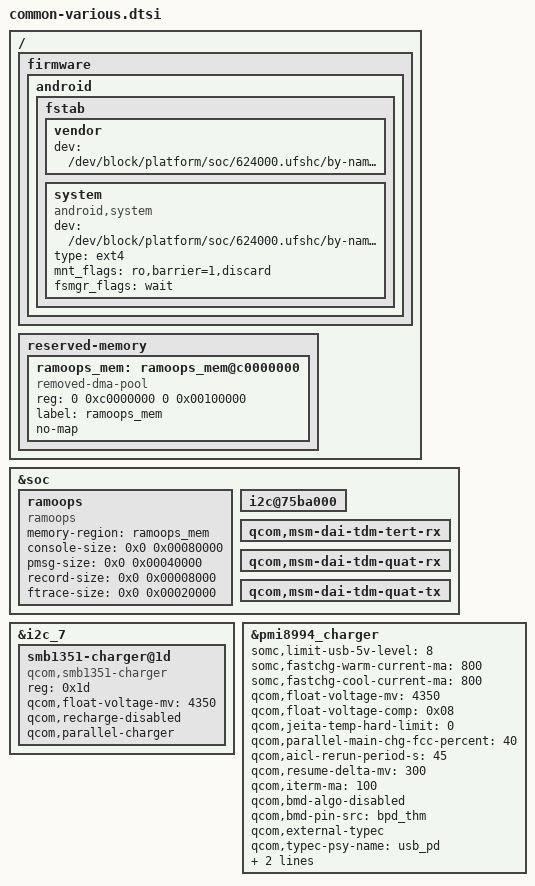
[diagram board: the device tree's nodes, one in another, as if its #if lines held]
/* Copyright (c) 2018 The LineageOS Project. All rights reserved.
 *
 * This program is free software; you can redistribute it and/or modify
 * it under the terms of the GNU General Public License version 2 and
 * only version 2 as published by the Free Software Foundation.
 *
 * This program is distributed in the hope that it will be useful,
 * but WITHOUT ANY WARRANTY; without even the implied warranty of
 * MERCHANTABILITY or FITNESS FOR A PARTICULAR PURPOSE.  See the
 * GNU General Public License for more details.
 */

/ {
	firmware: firmware {
		android {
			/delete-node/ vbmeta;
			fstab {
#ifdef CONFIG_LGE_MSM8996_ENABLE_VENDOR
				vendor {
					dev = "/dev/block/platform/soc/624000.ufshc/by-name/vendor";
				};
#else
				/delete-node/ vendor;
#endif
				system {
					compatible = "android,system";
					dev = "/dev/block/platform/soc/624000.ufshc/by-name/system";
					type = "ext4";
					mnt_flags = "ro,barrier=1,discard";
					fsmgr_flags = "wait";
					status = "ok";
				};
			};
		};
	};
};

/ {
	reserved-memory {
		ramoops_mem: ramoops_mem@c0000000 {
			compatible = "removed-dma-pool";
			reg = <0 0xc0000000 0 0x00100000>;
			label = "ramoops_mem";
			no-map;
		};
	};
};

&soc {
	ramoops {
		compatible = "ramoops";
		memory-region = <&ramoops_mem>;
		console-size = <0x0 0x00080000>;
		pmsg-size    = <0x0 0x00040000>;
		record-size  = <0x0 0x00008000>;
		ftrace-size  = <0x0 0x00020000>;
		status = "ok";
	};

	i2c@75ba000 {
		/delete-node/ synaptics@20;
	};

	/delete-node/ gen-vkeys;

	qcom,msm-dai-tdm-tert-rx {
		/delete-property/ pinctrl-names;
		/delete-property/ pinctrl-0;
		/delete-property/ pinctrl-1;
	};

	qcom,msm-dai-tdm-quat-rx {
		/delete-property/ pinctrl-names;
		/delete-property/ pinctrl-0;
		/delete-property/ pinctrl-1;
	};

	qcom,msm-dai-tdm-quat-tx {
		/delete-property/ pinctrl-names;
		/delete-property/ pinctrl-0;
		/delete-property/ pinctrl-1;
	};
};

&i2c_7 {
	/delete-node/ silabs4705@11;
};

&i2c_7 {
	smb1351-charger@1d {
		compatible = "qcom,smb1351-charger";
		reg = <0x1d>;
		qcom,float-voltage-mv = <4350>;
		qcom,recharge-disabled;
		qcom,parallel-charger;
	};
};

&pmi8994_charger {
	somc,limit-usb-5v-level = <8>;
	somc,fastchg-warm-current-ma = <800>;
	somc,fastchg-cool-current-ma = <800>;
	qcom,float-voltage-mv = <4350>;
	qcom,float-voltage-comp = <0x08>;
	qcom,jeita-temp-hard-limit = <0>;
	/delete-property/ qcom,chg-inhibit-fg;
	qcom,parallel-main-chg-fcc-percent = <40>;
	qcom,aicl-rerun-period-s = <45>;
	qcom,resume-delta-mv = <300>;
	qcom,iterm-ma = <100>;
	qcom,bmd-algo-disabled;
	qcom,bmd-pin-src="bpd_thm";
	qcom,external-typec;
	qcom,typec-psy-name = "usb_pd";
#ifdef CONFIG_MACH_MSM8996_LUCYE
	qcom,dc-psy-type = "Wireless";
	qcom,dc-psy-ma = <900>;
#endif
};
